# K1921VG1T register map
Vendor: NIIET; Series: K1921VGx; File version: 2.8
CPU: other r0p1, little endian, MPU, FPU, 4 interrupt priority bits
Registers are 32-bit, read-write, reset 0x0 unless marked. A register's access mark holds for its fields unless they carry their own. Offsets are from the block's base; [hi:lo] are bit positions; lines under a group give offsets from that group; {n}, {i} and the like mark numbered series.

## I2C0 — I2C control registers
Base 0x52018000
Same registers: I2C1 0x52019000, I2C2 0x5201A000, I2C3 0x5201B000
0x00 SDA — Data register
  [7:0] DATA
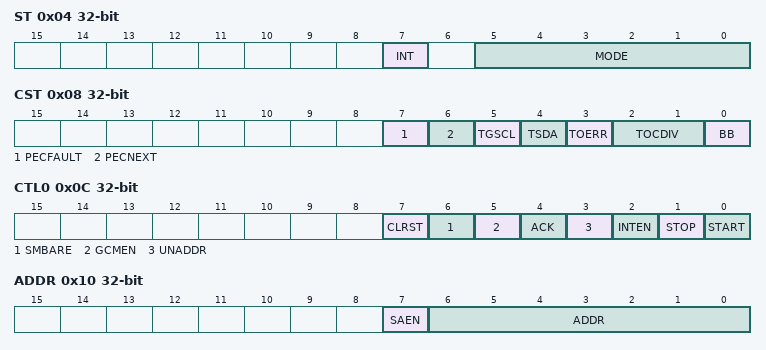
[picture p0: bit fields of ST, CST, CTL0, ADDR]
0x04 ST ro — Status register
  [7] INT — Interrupt flag
  [5:0] MODE — Status code
    0=IDLE (General - Idle, no valid status information available); 1=STDONE (FS master - Start condition generated); 2=RSDONE (FS master - Repeated start condition generated); 3=IDLARL (FS master - Arbitration lost, unaddressed slave mode entered); 4=MTADPA (FS master transmit - Slave address sent, positive ACK); 5=MTADNA (FS master transmit - Slave address sent, negative ACK); 6=MTDAPA (FS master transmit - Data byte sent, positive ACK); 7=MTDANA (FS master transmit - Data byte sent, negative ACK); 8=MRADPA (FS master receive - Slave addres sent, positive ACK); 9=MRADNA (FS master receive - Slave addres sent, negative ACK); 10=MRDAPA (FS master receive - Data byte received, positive ACK); 11=MRDANA (FS master receive - Data byte received, negative ACK); 12=MTMCER (FS master - Mastercode transmitted, error detected (positive ACK)); 16=SRADPA (FS slave receive - Slave address received, positive ACK); 17=SRAAPA (FS slave receive - Slave address received after arbitration loss, positive ACK); 18=SRDAPA (FS slave receive - Data byte received, positive ACK); 19=SRDANA (FS slave receive - Data byte received, negative ACK); 20=STADPA (FS slave transmit - Slave address received, positive ACK); 21=STAAPA (FS slave transmit - Slave address received, negative ACK); 22=STDAPA (FS slave transmit - Data byte sent, positive ACK); 23=STDANA (FS slave transmit - Data byte sent, negative ACK); 24=SATADP (FS slave transmit alert response - Alert response address received, positive ACK); 25=SATAAP (FS slave transmit alert response - Alert response address received after arbitration loss, positive ACK); 26=SATDAP (FS slave transmit alert response - Alert response data byte sent, positive ACK); 27=SATDAN (FS slave transmit alert response - Alert response data byte sent, negative ACK); 28=SSTOP (FS slave - Slave mode stop condition detected); 29=SGADPA (FS slave - Global call address received, positive ACK); 30=SDAAPA (FS slave - Global call address received after arbitration loss, positive ACK); 31=BERROR (General - Bus error detected (invalid start or stop condition); 33=HMTMCOK (HS master - Master code transmitted OK - switched to HS mode); 34=HRSDONE (HS master - Repeated start condition generated); 35=HIDLARL (HS master - Arbitration lost, HS unaddressed slave mode entered); 36=HMTADPA (HS master transmit - Slave address sent, positive ACK); 37=HMTADNA (HS master transmit - Slave address sent, negative ACK); 38=HMTDAPA (HS master transmit - Data byte sent, positive ACK); 39=HMTDANA (HS master transmit - Data byte sent, negative ACK); 40=HMRADPA (HS master receive - Slave address sent, positive ACK); 41=HMRADNA (HS master receive - Slave address sent, negative ACK); 42=HMRDAPA (HS master receive - Data byte received, positive ACK); 43=HMRDANA (HS master receive - Data byte received, negative ACK); 48=HSRADPA (HS slave receive - Slave address received, positive ACK); 50=HSRDAPA (HS slave receive - Data byte received, positive ACK); 51=HSRDANA (HS slave receive - Data byte received, negative ACK); 52=HSTADPA (HS slave transmit - Slave address received, positive ACK); 54=HSTDAPA (HS slave transmit - Data byte sent, positive ACK); 55=HSTDANA (HS slave transmit - Data byte sent, negative ACK)
0x08 CST — Status and control register
  [7] PECFAULT — Error flag
  [6] PECNEXT — Bit control transmit CRC
  [5] TGSCL — Bit switch SCL
  [4] TSDA — Bit test SDA
  [3] TOERR — Flag error simple bus
  [2:1] TOCDIV — Coeff. div
    0=disable clock; 1=Div4 (clock divided by 4); 2=Div8 (clock divided by 8); 3=Div16 (clock divided by 16)
  [0] BB — Flag employment bus
0x0C CTL0 — Control register 0
  [7] CLRST — Bit reset flag interrupt
  [6] SMBARE — Control bit part a response to the response address
  [5] GCMEN — Control bit part a response to the general call address
  [4] ACK — Acknowledgment bit reception
  [3] UNADDR — Unaddress mode, slave response to any address
  [2] INTEN — Interrupt enable bit
  [1] STOP — Stop bit
  [0] START — Start bit
0x10 ADDR — Register own address
  [7] SAEN — Enable bit address recognition
  [6:0] ADDR — Own 7-bit address
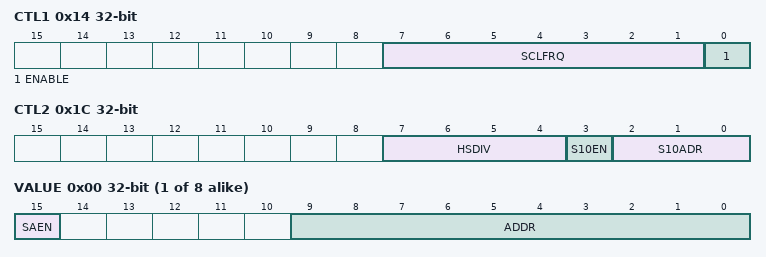
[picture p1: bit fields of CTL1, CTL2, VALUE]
0x14 CTL1 — Control register 1
  [7:1] SCLFRQ — Field frequency selection signal at pin SCL in master mode (bits [6:0])
  [0] ENABLE — Enable I2C
0x18 TOPR — Prescaler load register
  [7:0] SMBTOPR — Prescaler reload value field
0x1C CTL2 — Control register 2
  [7:4] HSDIV — Field frequency selection signal at pin SCL in HS master mode (bits [3:0])
  [3] S10EN — Bit enabled 10-bit addressing slave
  [2:0] S10ADR — Upper bits of 10-bit slave address
0x20 CTL3 — Control register 3
  [7:0] SCLFRQ — Field frequency selection signal at pin SCL in master mode (bits [14:7])
0x24 CTL4 — Control Register 4
  [7:0] HSDIV — Field frequency selection signal at pin SCL in HS master mode (bits [11:4])
{0x28+4i} EADDR[{i}] (i=0..7) group
  0x00 VALUE — Extended address Register
    [15] SAEN — Enable bit address recognition
    [9:0] ADDR — Additional adress
